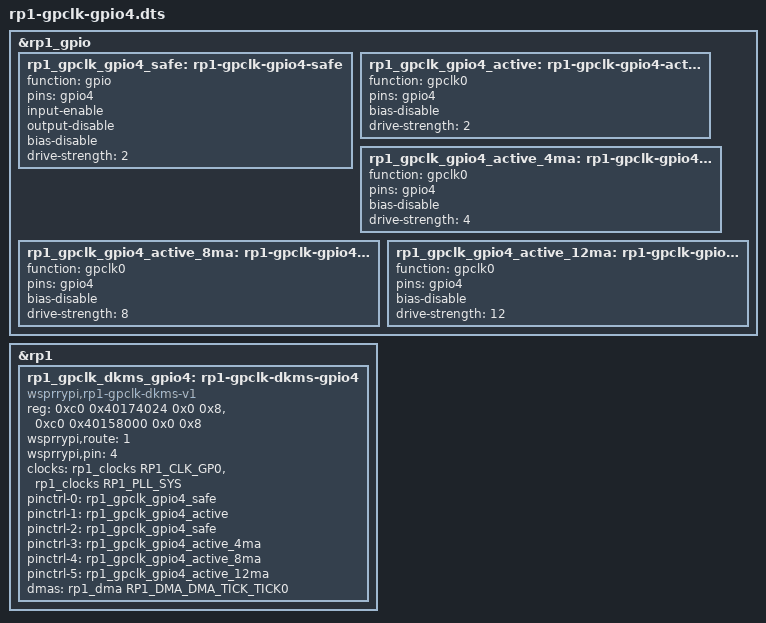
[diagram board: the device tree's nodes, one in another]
// SPDX-License-Identifier: GPL-2.0-only OR MIT
/dts-v1/;
/plugin/;

#include <dt-bindings/clock/rp1.h>
#include <dt-bindings/mfd/rp1.h>

&rp1_gpio {
	rp1_gpclk_gpio4_safe: rp1-gpclk-gpio4-safe {
		function = "gpio";
		pins = "gpio4";
		input-enable;
		output-disable;
		bias-disable;
		drive-strength = <2>;
	};

	rp1_gpclk_gpio4_active: rp1-gpclk-gpio4-active {
		function = "gpclk0";
		pins = "gpio4";
		bias-disable;
		drive-strength = <2>;
	};
	rp1_gpclk_gpio4_active_4ma: rp1-gpclk-gpio4-active-4ma {
		function = "gpclk0";
		pins = "gpio4";
		bias-disable;
		drive-strength = <4>;
	};

	rp1_gpclk_gpio4_active_8ma: rp1-gpclk-gpio4-active-8ma {
		function = "gpclk0";
		pins = "gpio4";
		bias-disable;
		drive-strength = <8>;
	};

	rp1_gpclk_gpio4_active_12ma: rp1-gpclk-gpio4-active-12ma {
		function = "gpclk0";
		pins = "gpio4";
		bias-disable;
		drive-strength = <12>;
	};
};

&rp1 {
	rp1_gpclk_dkms_gpio4: rp1-gpclk-dkms-gpio4 {
		compatible = "wsprrypi,rp1-gpclk-dkms-v1";
		reg = <0xc0 0x40174024 0x0 0x8>,
		      <0xc0 0x40158000 0x0 0x8>;
		reg-names = "tick-dma0", "dma-tick0";
		wsprrypi,route = <1>;
		wsprrypi,pin = <4>;
		clocks = <&rp1_clocks RP1_CLK_GP0>, <&rp1_clocks RP1_PLL_SYS>;
		clock-names = "gpclk", "parent";
		pinctrl-names = "default", "active", "safe",
				"active-4ma", "active-8ma", "active-12ma";
		pinctrl-0 = <&rp1_gpclk_gpio4_safe>;
		pinctrl-1 = <&rp1_gpclk_gpio4_active>;
		pinctrl-2 = <&rp1_gpclk_gpio4_safe>;
		pinctrl-3 = <&rp1_gpclk_gpio4_active_4ma>;
		pinctrl-4 = <&rp1_gpclk_gpio4_active_8ma>;
		pinctrl-5 = <&rp1_gpclk_gpio4_active_12ma>;
		dmas = <&rp1_dma RP1_DMA_DMA_TICK_TICK0>;
		dma-names = "tx";
		status = "okay";
	};
};
